# MKE15Z7 register map
Vendor: Freescale Semiconductor, Inc.; Series: Kinetis_E; File version: 1.6
CPU: CM0PLUS r0p0, little endian, no MPU, no FPU, VTOR, 2 interrupt priority bits
Registers are 32-bit, read-write, reset 0x0 unless marked. A register's access mark holds for its fields unless they carry their own. Offsets are from the block's base; [hi:lo] are bit positions; {n}, {i} and the like mark numbered series; 'fields as' and 'values as' point back to an identical list.

## TRGMUX0 — TRGMUX
Base 0x40062000
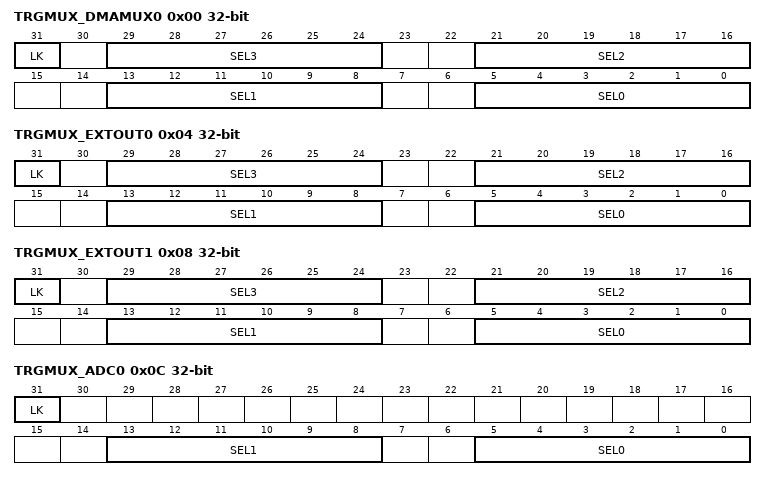
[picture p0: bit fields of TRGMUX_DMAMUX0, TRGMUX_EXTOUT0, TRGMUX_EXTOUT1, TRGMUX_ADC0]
0x00 TRGMUX_DMAMUX0 — TRGMUX Register
  [31] LK ro — Enable
    0=Register can be written; 1=Register cannot be written until the next system Reset
  [8n+5:8n] SEL{n} (n=0..3) — Trigger MUX Input {n} Source Select
0x04 TRGMUX_EXTOUT0 — TRGMUX Register
  fields as TRGMUX_DMAMUX0
0x08 TRGMUX_EXTOUT1 — TRGMUX Register
  fields as TRGMUX_DMAMUX0
0x0C TRGMUX_ADC0 — TRGMUX Register
  [31] LK ro — Enable
    values as TRGMUX_DMAMUX0.LK
  [13:8] SEL1 — Trigger MUX Input 1 Source Select
  [5:0] SEL0 — Trigger MUX Input 0 Source Select
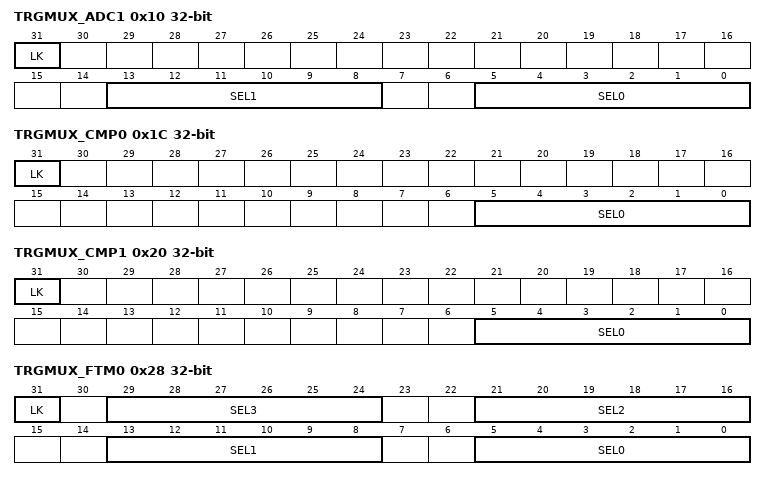
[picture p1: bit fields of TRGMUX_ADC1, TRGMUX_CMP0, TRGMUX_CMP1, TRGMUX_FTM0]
0x10 TRGMUX_ADC1 — TRGMUX Register
  fields as TRGMUX_ADC0
0x1C TRGMUX_CMP0 — TRGMUX Register
  [31] LK ro — Enable
    values as TRGMUX_DMAMUX0.LK
  [5:0] SEL0 — Trigger MUX Input 0 Source Select
0x20 TRGMUX_CMP1 — TRGMUX Register
  fields as TRGMUX_CMP0
0x28 TRGMUX_FTM0 — TRGMUX Register
  fields as TRGMUX_DMAMUX0
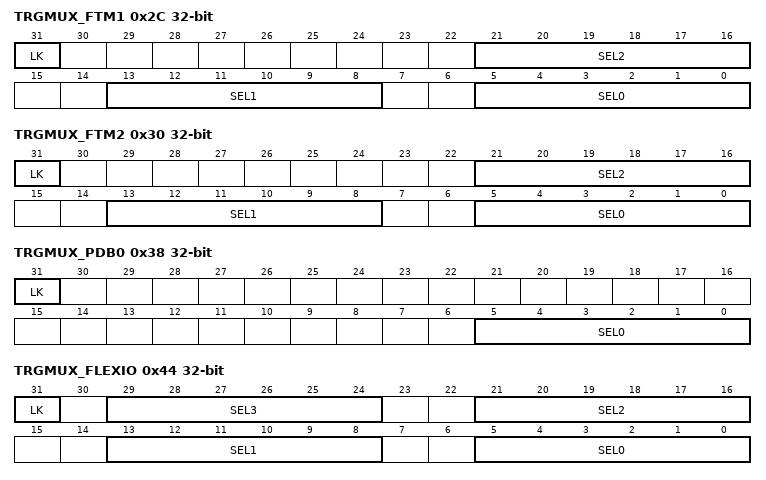
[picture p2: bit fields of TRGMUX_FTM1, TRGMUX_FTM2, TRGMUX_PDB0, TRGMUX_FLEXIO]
0x2C TRGMUX_FTM1 — TRGMUX Register
  [31] LK ro — Enable
    values as TRGMUX_DMAMUX0.LK
  [21:16] SEL2 — Trigger MUX Input 2 Source Select
  [13:8] SEL1 — Trigger MUX Input 1 Source Select
  [5:0] SEL0 — Trigger MUX Input 0 Source Select
0x30 TRGMUX_FTM2 — TRGMUX Register
  fields as TRGMUX_FTM1
0x38 TRGMUX_PDB0 — TRGMUX Register
  fields as TRGMUX_CMP0
0x44 TRGMUX_FLEXIO — TRGMUX Register
  fields as TRGMUX_DMAMUX0
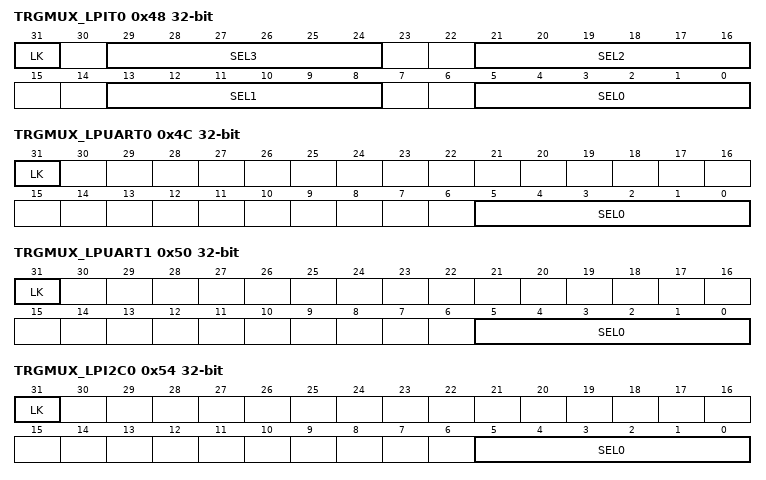
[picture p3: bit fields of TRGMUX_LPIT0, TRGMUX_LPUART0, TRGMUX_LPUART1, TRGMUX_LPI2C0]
0x48 TRGMUX_LPIT0 — TRGMUX Register
  fields as TRGMUX_DMAMUX0
0x4C TRGMUX_LPUART0 — TRGMUX Register
  fields as TRGMUX_CMP0
0x50 TRGMUX_LPUART1 — TRGMUX Register
  fields as TRGMUX_CMP0
0x54 TRGMUX_LPI2C0 — TRGMUX Register
  fields as TRGMUX_CMP0
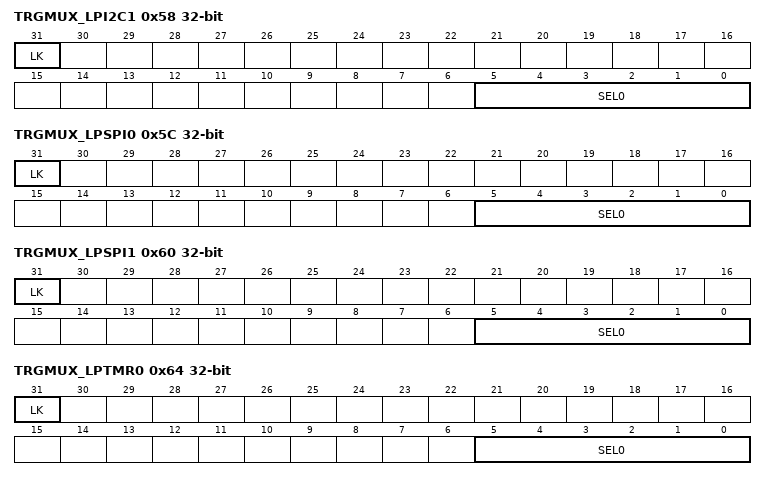
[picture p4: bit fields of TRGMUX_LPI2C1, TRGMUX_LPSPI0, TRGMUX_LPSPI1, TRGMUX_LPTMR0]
0x58 TRGMUX_LPI2C1 — TRGMUX Register
  fields as TRGMUX_CMP0
0x5C TRGMUX_LPSPI0 — TRGMUX Register
  fields as TRGMUX_CMP0
0x60 TRGMUX_LPSPI1 — TRGMUX Register
  fields as TRGMUX_CMP0
0x64 TRGMUX_LPTMR0 — TRGMUX Register
  fields as TRGMUX_CMP0
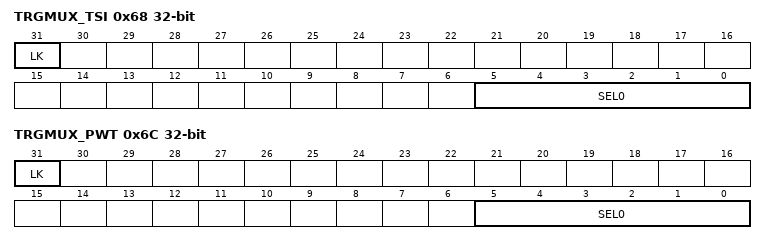
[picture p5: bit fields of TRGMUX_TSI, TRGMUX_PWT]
0x68 TRGMUX_TSI — TRGMUX Register
  fields as TRGMUX_CMP0
0x6C TRGMUX_PWT — TRGMUX Register
  fields as TRGMUX_CMP0

## TRGMUX1 — TRGMUX
Base 0x40063000
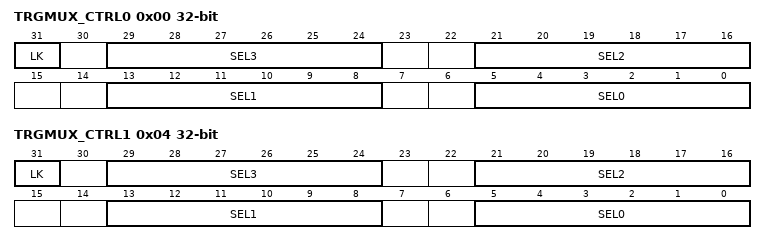
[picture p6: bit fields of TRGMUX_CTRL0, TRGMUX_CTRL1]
0x00 TRGMUX_CTRL0 — TRGMUX Register
  [31] LK ro — Enable
    0=Register can be written; 1=Register cannot be written until the next system Reset
  [8n+5:8n] SEL{n} (n=0..3) — Trigger MUX Input {n} Source Select
0x04 TRGMUX_CTRL1 — TRGMUX Register
  fields as TRGMUX_CTRL0

## PMC
Base 0x4007D000; register names take the prefix PMC_
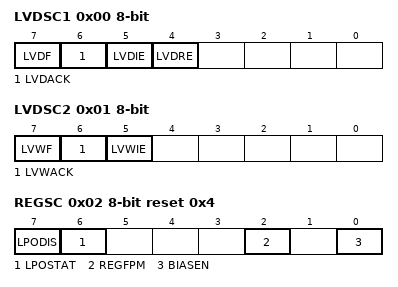
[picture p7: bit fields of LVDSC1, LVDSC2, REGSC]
0x00 LVDSC1 8-bit — Low Voltage Detect Status and Control 1 Register
  [7] LVDF ro — Low Voltage Detect Flag
    0=Low-voltage event not detected; 1=Low-voltage event detected
  [6] LVDACK wo — Low Voltage Detect Acknowledge
  [5] LVDIE — Low Voltage Detect Interrupt Enable
    0=Hardware interrupt disabled (use polling); 1=Request a hardware interrupt when LVDF = 1
  [4] LVDRE — Low Voltage Detect Reset Enable
    0=No system resets on low voltage detect events; 1=If the supply voltage falls below VLVD, a system reset will be generated
0x01 LVDSC2 8-bit — Low Voltage Detect Status and Control 2 Register
  [7] LVWF ro — Low-Voltage Warning Flag
    0=Low-voltage warning event not detected; 1=Low-voltage warning event detected
  [6] LVWACK wo — Low-Voltage Warning Acknowledge
  [5] LVWIE — Low-Voltage Warning Interrupt Enable
    0=Hardware interrupt disabled (use polling); 1=Request a hardware interrupt when LVWF=1
0x02 REGSC 8-bit reset 0x4 — Regulator Status and Control Register
  [7] LPODIS — LPO Disable Bit
    0=Low power oscillator enabled; 1=Low power oscillator disabled
  [6] LPOSTAT ro — LPO Status Bit
    0=Low power oscillator in low phase; 1=Low power oscillator in high phase
  [2] REGFPM ro — Regulator in Full Performance Mode Status Bit
    0=Regulator is in low power mode or transition to/from; 1=Regulator is in full performance mode
  [0] BIASEN — Bias Enable Bit
    0=Biasing disabled, core logic can run in full performance; 1=Biasing enabled, core logic is slower and there are restrictions in allowed system clock speed (see device level specification for details)
0x04 LPOTRIM 8-bit — Low Power Oscillator Trim Register
  [4:0] LPOTRIM — LPO trimming bits
